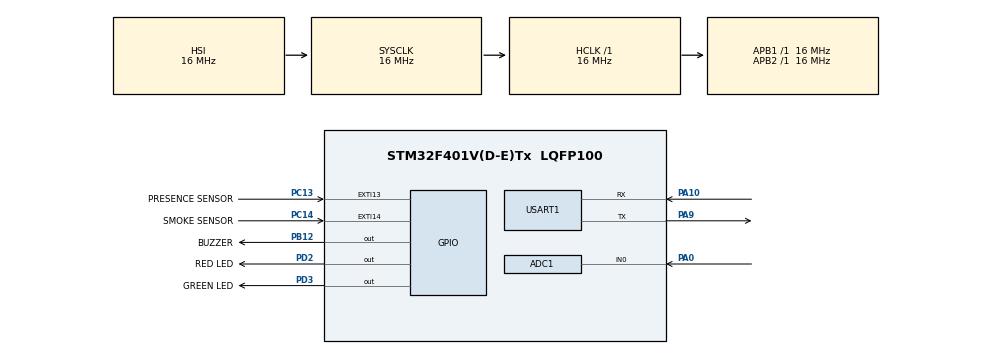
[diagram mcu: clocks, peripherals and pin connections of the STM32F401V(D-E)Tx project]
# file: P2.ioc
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ADC1.Channel-5\#ChannelRegularConversion=ADC_CHANNEL_0
ADC1.ContinuousConvMode=ENABLE
ADC1.NbrOfConversionFlag=1
ADC1.Rank-5\#ChannelRegularConversion=1
ADC1.SamplingTime-5\#ChannelRegularConversion=ADC_SAMPLETIME_3CYCLES
ADC1.ScanConvMode=ENABLE
ADC1.master=1
Mcu.Family=STM32F4
Mcu.Name=STM32F401V(D-E)Tx
Mcu.Package=LQFP100
NVIC.ADC_IRQn=true\:0\:0\:false\:false\:true\:true\:true\:true
NVIC.EXTI15_10_IRQn=true\:0\:0\:true\:false\:true\:true\:true\:true
NVIC.PriorityGroup=NVIC_PRIORITYGROUP_4
PA0-WKUP.Signal=SharedAnalog_PA0
PA10.Mode=Asynchronous
PA10.Signal=USART1_RX
PA13.Mode=Serial_Wire
PA13.Signal=SYS_JTMS-SWDIO
PA14.Mode=Serial_Wire
PA14.Signal=SYS_JTCK-SWCLK
PA9.Mode=Asynchronous
PA9.Signal=USART1_TX
PB12.GPIO_Label=BUZZER
PB12.Signal=GPIO_Output
PC13-ANTI_TAMP.GPIO_Label=PRESENCE SENSOR
PC13-ANTI_TAMP.GPIO_ModeDefaultEXTI=GPIO_MODE_IT_RISING
PC13-ANTI_TAMP.GPIO_PuPd=GPIO_PULLUP
PC13-ANTI_TAMP.Signal=GPXTI13
PC14-OSC32_IN.GPIO_Label=SMOKE SENSOR
PC14-OSC32_IN.GPIO_ModeDefaultEXTI=GPIO_MODE_IT_RISING
PC14-OSC32_IN.GPIO_PuPd=GPIO_PULLUP
PC14-OSC32_IN.Signal=GPXTI14
PD2.GPIO_Label=RED LED
PD2.Signal=GPIO_Output
PD3.GPIO_Label=GREEN LED
PD3.Signal=GPIO_Output
ProjectManager.HeapSize=0x200
ProjectManager.StackSize=0x400
ProjectManager.TargetToolchain=STM32CubeIDE
RCC.AHBFreq_Value=16000000
RCC.APB1Freq_Value=16000000
RCC.APB2Freq_Value=16000000
RCC.CortexFreq_Value=16000000
RCC.HSE_VALUE=25000000
RCC.HSI_VALUE=16000000
RCC.LSE_VALUE=32768
RCC.SYSCLKFreq_VALUE=16000000
RCC.VCOOutputFreq_Value=192000000
SH.SharedAnalog_PA0.0=GPIO_Analog
SH.SharedAnalog_PA0.1=ADC1_IN0,IN0
USART1.VirtualMode=VM_ASYNC
board=custom

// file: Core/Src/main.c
/* USER CODE BEGIN Header */
/**
  ******************************************************************************
  * @file           : main.c
  * @brief          : Main program body
  ******************************************************************************
  * @attention
  *
  * Copyright (c) 2024 STMicroelectronics.
  * All rights reserved.
  *
  * This software is licensed under terms that can be found in the LICENSE file
  * in the root directory of this software component.
  * If no LICENSE file comes with this software, it is provided AS-IS.
  *
  ******************************************************************************
  */
/* USER CODE END Header */
#include "main.h"
#include <stdio.h>
#include <string.h>

ADC_HandleTypeDef hadc1;

UART_HandleTypeDef huart1;

void SystemClock_Config(void);
static void MX_GPIO_Init(void);
static void MX_ADC1_Init(void);
static void MX_USART1_UART_Init(void);

int main(void)
{

  /* MCU Configuration--------------------------------------------------------*/

  /* Reset of all peripherals, Initializes the Flash interface and the Systick. */
  HAL_Init();

  /* Configure the system clock */
  SystemClock_Config();

  /* Initialize all configured peripherals */
  MX_GPIO_Init();
  MX_ADC1_Init();
  MX_USART1_UART_Init();

  uint16_t raw ;

       while (1)
       {
     	  HAL_ADC_Start(&hadc1);
     	  HAL_ADC_PollForConversion(&hadc1, HAL_MAX_DELAY);
     	  raw =HAL_ADC_GetValue(&hadc1);
     	  HAL_ADC_Stop(&hadc1);
     	  int Result=0;
     	  Result=(int)raw;
     	  int ResultFinale=0;
     	  ResultFinale= (80*(Result-4)/4091);
     	  char msg2[50];
     	  uint16_t raw2 ;
     	  raw2 = 200; //= (uint16_t) ResultFinale;
     	  sprintf(msg2,"%u\r\n", raw2);
     	 // sprintf(msg2, "Raw: %d, SensorValue: %d\r\n", raw, ResultFinale);
     	  HAL_UART_Transmit(&huart1,(uint8_t *) msg2, strlen(msg2), HAL_MAX_DELAY);

     	  HAL_Delay(500);
     	  HAL_NVIC_EnableIRQ(EXTI15_10_IRQn);
           // Set LEDs and Buzzer
           HAL_GPIO_WritePin(GPIOD, GPIO_PIN_3, GPIO_PIN_SET); // Green LED ON
           HAL_GPIO_WritePin(GPIOD, GPIO_PIN_2, GPIO_PIN_RESET); // Red LED OFF
           HAL_GPIO_WritePin(GPIOB, GPIO_PIN_12, GPIO_PIN_RESET); // Buzzer OFF

           // Read ADC valuE

           HAL_Delay(500);
           if (ResultFinale<40){
         	  uint16_t j ;
         	  for(j=0;j<2000;j++){
 				  HAL_GPIO_WritePin(GPIOD, GPIO_PIN_2, GPIO_PIN_SET);
 				  HAL_GPIO_WritePin(GPIOB, GPIO_PIN_12, GPIO_PIN_SET);
 				  HAL_GPIO_WritePin(GPIOD, GPIO_PIN_3, GPIO_PIN_RESET);}
           }
           // Delay or perform other tasks as needed

       }
   }

void SystemClock_Config(void)
{
  RCC_OscInitTypeDef RCC_OscInitStruct = {0};
  RCC_ClkInitTypeDef RCC_ClkInitStruct = {0};

  /** Configure the main internal regulator output voltage
  */
  __HAL_RCC_PWR_CLK_ENABLE();
  __HAL_PWR_VOLTAGESCALING_CONFIG(PWR_REGULATOR_VOLTAGE_SCALE2);

  /** Initializes the RCC Oscillators according to the specified parameters
  * in the RCC_OscInitTypeDef structure.
  */
  RCC_OscInitStruct.OscillatorType = RCC_OSCILLATORTYPE_HSI;
  RCC_OscInitStruct.HSIState = RCC_HSI_ON;
  RCC_OscInitStruct.HSICalibrationValue = RCC_HSICALIBRATION_DEFAULT;
  RCC_OscInitStruct.PLL.PLLState = RCC_PLL_NONE;
  if (HAL_RCC_OscConfig(&RCC_OscInitStruct) != HAL_OK)
  {
    Error_Handler();
  }

  /** Initializes the CPU, AHB and APB buses clocks
  */
  RCC_ClkInitStruct.ClockType = RCC_CLOCKTYPE_HCLK|RCC_CLOCKTYPE_SYSCLK
                              |RCC_CLOCKTYPE_PCLK1|RCC_CLOCKTYPE_PCLK2;
  RCC_ClkInitStruct.SYSCLKSource = RCC_SYSCLKSOURCE_HSI;
  RCC_ClkInitStruct.AHBCLKDivider = RCC_SYSCLK_DIV1;
  RCC_ClkInitStruct.APB1CLKDivider = RCC_HCLK_DIV1;
  RCC_ClkInitStruct.APB2CLKDivider = RCC_HCLK_DIV1;

  if (HAL_RCC_ClockConfig(&RCC_ClkInitStruct, FLASH_LATENCY_0) != HAL_OK)
  {
    Error_Handler();
  }
}

static void MX_ADC1_Init(void)
{

  ADC_ChannelConfTypeDef sConfig = {0};

  /** Configure the global features of the ADC (Clock, Resolution, Data Alignment and number of conversion)
  */
  hadc1.Instance = ADC1;
  hadc1.Init.ClockPrescaler = ADC_CLOCK_SYNC_PCLK_DIV2;
  hadc1.Init.Resolution = ADC_RESOLUTION_12B;
  hadc1.Init.ScanConvMode = ENABLE;
  hadc1.Init.ContinuousConvMode = ENABLE;
  hadc1.Init.DiscontinuousConvMode = DISABLE;
  hadc1.Init.ExternalTrigConvEdge = ADC_EXTERNALTRIGCONVEDGE_NONE;
  hadc1.Init.ExternalTrigConv = ADC_SOFTWARE_START;
  hadc1.Init.DataAlign = ADC_DATAALIGN_RIGHT;
  hadc1.Init.NbrOfConversion = 1;
  hadc1.Init.DMAContinuousRequests = DISABLE;
  hadc1.Init.EOCSelection = ADC_EOC_SINGLE_CONV;
  if (HAL_ADC_Init(&hadc1) != HAL_OK)
  {
    Error_Handler();
  }

  /** Configure for the selected ADC regular channel its corresponding rank in the sequencer and its sample time.
  */
  sConfig.Channel = ADC_CHANNEL_0;
  sConfig.Rank = 1;
  sConfig.SamplingTime = ADC_SAMPLETIME_15CYCLES;
  if (HAL_ADC_ConfigChannel(&hadc1, &sConfig) != HAL_OK)
  {
    Error_Handler();
  }

}

static void MX_USART1_UART_Init(void)
{

  huart1.Instance = USART1;
  huart1.Init.BaudRate = 115200;
  huart1.Init.WordLength = UART_WORDLENGTH_8B;
  huart1.Init.StopBits = UART_STOPBITS_1;
  huart1.Init.Parity = UART_PARITY_NONE;
  huart1.Init.Mode = UART_MODE_TX_RX;
  huart1.Init.HwFlowCtl = UART_HWCONTROL_NONE;
  huart1.Init.OverSampling = UART_OVERSAMPLING_16;
  if (HAL_UART_Init(&huart1) != HAL_OK)
  {
    Error_Handler();
  }

}

static void MX_GPIO_Init(void)
{
  GPIO_InitTypeDef GPIO_InitStruct = {0};

  /* GPIO Ports Clock Enable */
  __HAL_RCC_GPIOC_CLK_ENABLE();
  __HAL_RCC_GPIOA_CLK_ENABLE();
  __HAL_RCC_GPIOB_CLK_ENABLE();
  __HAL_RCC_GPIOD_CLK_ENABLE();

  /*Configure GPIO pin Output Level */
  HAL_GPIO_WritePin(BUZZER_GPIO_Port, BUZZER_Pin, GPIO_PIN_RESET);

  /*Configure GPIO pin Output Level */
  HAL_GPIO_WritePin(GPIOD, RED_LED_Pin|GREEN_LED_Pin, GPIO_PIN_RESET);

  /*Configure GPIO pins : PRESENCE_SENSOR_Pin SMOKE_SENSOR_Pin */
  GPIO_InitStruct.Pin = PRESENCE_SENSOR_Pin|SMOKE_SENSOR_Pin;
  GPIO_InitStruct.Mode = GPIO_MODE_IT_RISING;
  GPIO_InitStruct.Pull = GPIO_PULLUP;
  HAL_GPIO_Init(GPIOC, &GPIO_InitStruct);

  /*Configure GPIO pin : BUZZER_Pin */
  GPIO_InitStruct.Pin = BUZZER_Pin;
  GPIO_InitStruct.Mode = GPIO_MODE_OUTPUT_PP;
  GPIO_InitStruct.Pull = GPIO_NOPULL;
  GPIO_InitStruct.Speed = GPIO_SPEED_FREQ_LOW;
  HAL_GPIO_Init(BUZZER_GPIO_Port, &GPIO_InitStruct);

  /*Configure GPIO pins : RED_LED_Pin GREEN_LED_Pin */
  GPIO_InitStruct.Pin = RED_LED_Pin|GREEN_LED_Pin;
  GPIO_InitStruct.Mode = GPIO_MODE_OUTPUT_PP;
  GPIO_InitStruct.Pull = GPIO_NOPULL;
  GPIO_InitStruct.Speed = GPIO_SPEED_FREQ_LOW;
  HAL_GPIO_Init(GPIOD, &GPIO_InitStruct);

  /* EXTI interrupt init*/
  HAL_NVIC_SetPriority(EXTI15_10_IRQn, 0, 0);
  HAL_NVIC_EnableIRQ(EXTI15_10_IRQn);

}

/* USER CODE BEGIN 4 */
void HAL_GPIO_EXTI_Callback(uint16_t GPIO_Pin)
{
	uint16_t i;

    if (GPIO_Pin == GPIO_PIN_13 || GPIO_Pin == GPIO_PIN_14)
    {
        for(i=0;i<20000;i++){
        	HAL_GPIO_WritePin(GPIOD, GPIO_PIN_2, GPIO_PIN_SET);
        	HAL_GPIO_WritePin(GPIOB, GPIO_PIN_12, GPIO_PIN_SET);
        	HAL_GPIO_WritePin(GPIOD, GPIO_PIN_3, GPIO_PIN_RESET);
        	printf("one person detected");
        }

        HAL_NVIC_DisableIRQ(EXTI15_10_IRQn);

    }
}
/* USER CODE END 4 */

void Error_Handler(void)
{
  __disable_irq();
  while (1)
  {
  }
}
